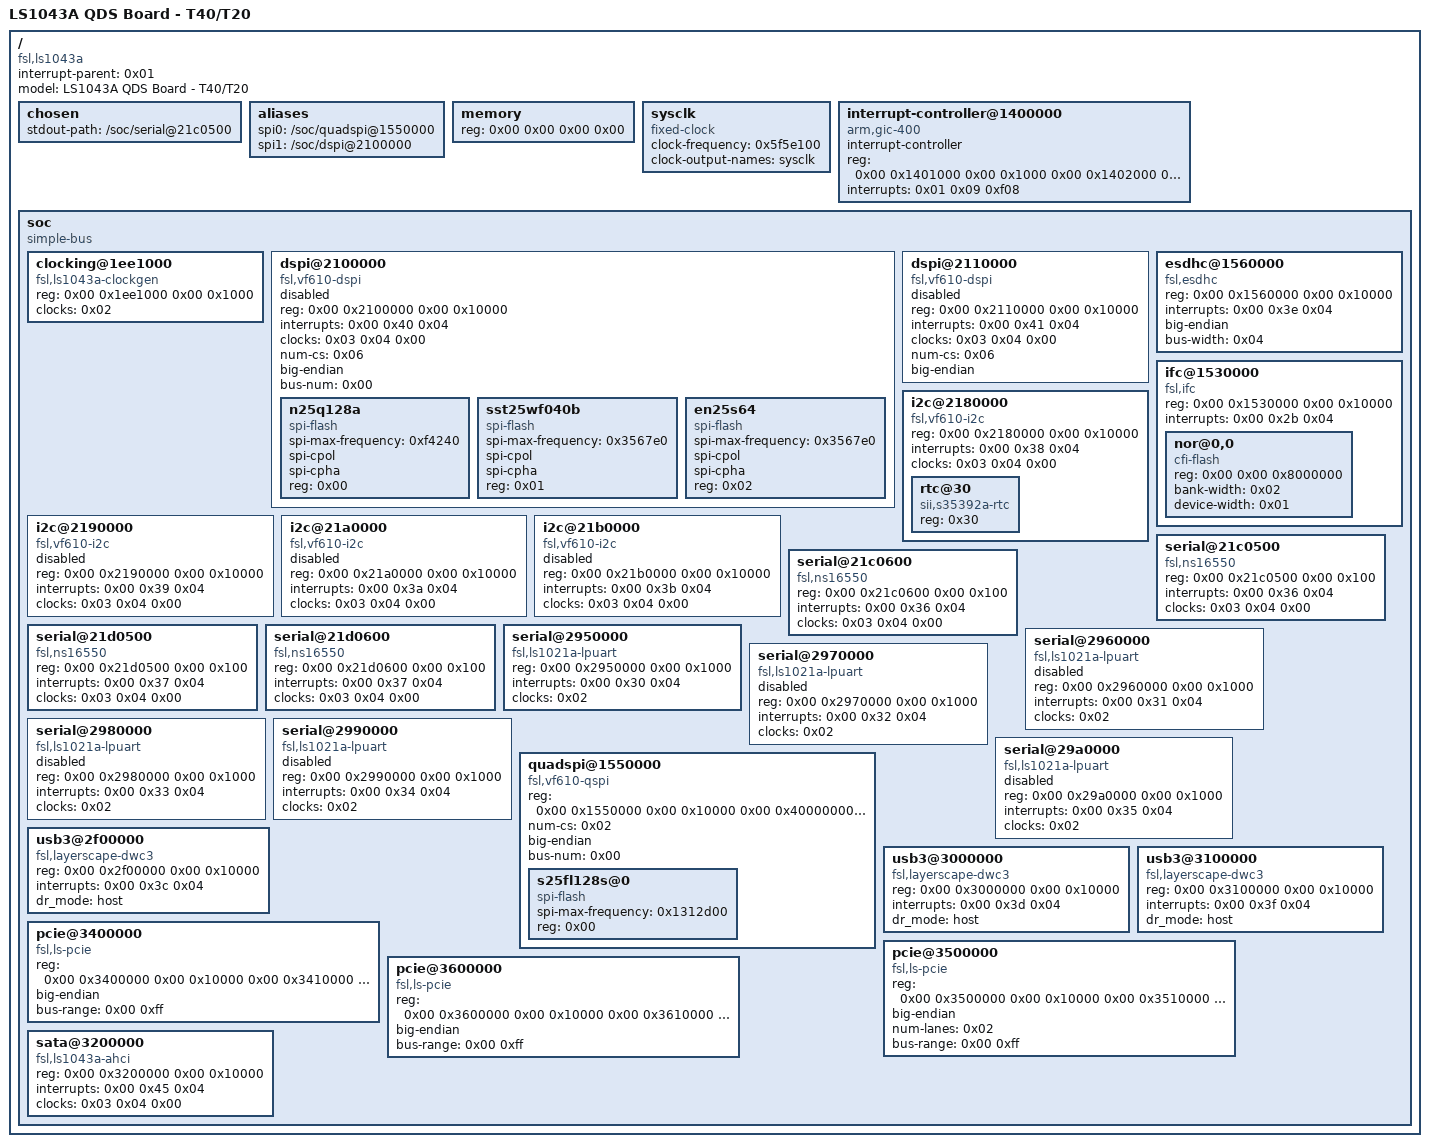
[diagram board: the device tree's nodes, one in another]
/dts-v1/;

/ {
	#address-cells = <0x02>;
	#size-cells = <0x02>;
	compatible = "fsl,ls1043a";
	interrupt-parent = <0x01>;
	model = "LS1043A QDS Board - T40/T20";

	chosen {
		stdout-path = "/soc/serial@21c0500";
	};

	aliases {
		spi0 = "/soc/quadspi@1550000";
		spi1 = "/soc/dspi@2100000";
	};

	memory {
		device_type = "memory";
		reg = <0x00 0x00 0x00 0x00>;
	};

	sysclk {
		compatible = "fixed-clock";
		#clock-cells = <0x00>;
		clock-frequency = <0x5f5e100>;
		clock-output-names = "sysclk";
		phandle = <0x02>;
	};

	interrupt-controller@1400000 {
		compatible = "arm,gic-400";
		#interrupt-cells = <0x03>;
		interrupt-controller;
		reg = <0x00 0x1401000 0x00 0x1000 0x00 0x1402000 0x00 0x2000 0x00 0x1404000 0x00 0x2000 0x00 0x1406000 0x00 0x2000>;
		interrupts = <0x01 0x09 0xf08>;
		phandle = <0x01>;
	};

	soc {
		compatible = "simple-bus";
		#address-cells = <0x02>;
		#size-cells = <0x02>;
		ranges;

		clocking@1ee1000 {
			compatible = "fsl,ls1043a-clockgen";
			reg = <0x00 0x1ee1000 0x00 0x1000>;
			#clock-cells = <0x02>;
			clocks = <0x02>;
			phandle = <0x03>;
		};

		dspi@2100000 {
			compatible = "fsl,vf610-dspi";
			#address-cells = <0x01>;
			#size-cells = <0x00>;
			reg = <0x00 0x2100000 0x00 0x10000>;
			interrupts = <0x00 0x40 0x04>;
			clock-names = "dspi";
			clocks = <0x03 0x04 0x00>;
			num-cs = <0x06>;
			big-endian;
			status = "disabled";
			bus-num = <0x00>;

			n25q128a {
				#address-cells = <0x01>;
				#size-cells = <0x01>;
				compatible = "spi-flash";
				spi-max-frequency = <0xf4240>;
				spi-cpol;
				spi-cpha;
				reg = <0x00>;
			};

			sst25wf040b {
				#address-cells = <0x01>;
				#size-cells = <0x01>;
				compatible = "spi-flash";
				spi-max-frequency = <0x3567e0>;
				spi-cpol;
				spi-cpha;
				reg = <0x01>;
			};

			en25s64 {
				#address-cells = <0x01>;
				#size-cells = <0x01>;
				compatible = "spi-flash";
				spi-max-frequency = <0x3567e0>;
				spi-cpol;
				spi-cpha;
				reg = <0x02>;
			};
		};

		dspi@2110000 {
			compatible = "fsl,vf610-dspi";
			#address-cells = <0x01>;
			#size-cells = <0x00>;
			reg = <0x00 0x2110000 0x00 0x10000>;
			interrupts = <0x00 0x41 0x04>;
			clock-names = "dspi";
			clocks = <0x03 0x04 0x00>;
			num-cs = <0x06>;
			big-endian;
			status = "disabled";
		};

		esdhc@1560000 {
			compatible = "fsl,esdhc";
			reg = <0x00 0x1560000 0x00 0x10000>;
			interrupts = <0x00 0x3e 0x04>;
			big-endian;
			bus-width = <0x04>;
		};

		ifc@1530000 {
			compatible = "fsl,ifc", "simple-bus";
			reg = <0x00 0x1530000 0x00 0x10000>;
			interrupts = <0x00 0x2b 0x04>;
			#address-cells = <0x02>;
			#size-cells = <0x01>;
			ranges = <0x00 0x00 0x00 0x60000000 0x8000000 0x01 0x00 0x00 0x7e800000 0x10000 0x02 0x00 0x00 0x7fb00000 0x100>;
			status = "okay";

			nor@0,0 {
				#address-cells = <0x01>;
				#size-cells = <0x01>;
				compatible = "cfi-flash";
				reg = <0x00 0x00 0x8000000>;
				bank-width = <0x02>;
				device-width = <0x01>;
			};
		};

		i2c@2180000 {
			compatible = "fsl,vf610-i2c";
			#address-cells = <0x01>;
			#size-cells = <0x00>;
			reg = <0x00 0x2180000 0x00 0x10000>;
			interrupts = <0x00 0x38 0x04>;
			clock-names = "i2c";
			clocks = <0x03 0x04 0x00>;
			status = "okay";

			rtc@30 {
				compatible = "sii,s35392a-rtc";
				reg = <0x30>;
			};
		};

		i2c@2190000 {
			compatible = "fsl,vf610-i2c";
			#address-cells = <0x01>;
			#size-cells = <0x00>;
			reg = <0x00 0x2190000 0x00 0x10000>;
			interrupts = <0x00 0x39 0x04>;
			clock-names = "i2c";
			clocks = <0x03 0x04 0x00>;
			status = "disabled";
		};

		i2c@21a0000 {
			compatible = "fsl,vf610-i2c";
			#address-cells = <0x01>;
			#size-cells = <0x00>;
			reg = <0x00 0x21a0000 0x00 0x10000>;
			interrupts = <0x00 0x3a 0x04>;
			clock-names = "i2c";
			clocks = <0x03 0x04 0x00>;
			status = "disabled";
		};

		i2c@21b0000 {
			compatible = "fsl,vf610-i2c";
			#address-cells = <0x01>;
			#size-cells = <0x00>;
			reg = <0x00 0x21b0000 0x00 0x10000>;
			interrupts = <0x00 0x3b 0x04>;
			clock-names = "i2c";
			clocks = <0x03 0x04 0x00>;
			status = "disabled";
		};

		serial@21c0500 {
			compatible = "fsl,ns16550", "ns16550a";
			reg = <0x00 0x21c0500 0x00 0x100>;
			interrupts = <0x00 0x36 0x04>;
			clocks = <0x03 0x04 0x00>;
			status = "okay";
		};

		serial@21c0600 {
			compatible = "fsl,ns16550", "ns16550a";
			reg = <0x00 0x21c0600 0x00 0x100>;
			interrupts = <0x00 0x36 0x04>;
			clocks = <0x03 0x04 0x00>;
			status = "okay";
		};

		serial@21d0500 {
			compatible = "fsl,ns16550", "ns16550a";
			reg = <0x00 0x21d0500 0x00 0x100>;
			interrupts = <0x00 0x37 0x04>;
			clocks = <0x03 0x04 0x00>;
		};

		serial@21d0600 {
			compatible = "fsl,ns16550", "ns16550a";
			reg = <0x00 0x21d0600 0x00 0x100>;
			interrupts = <0x00 0x37 0x04>;
			clocks = <0x03 0x04 0x00>;
		};

		serial@2950000 {
			compatible = "fsl,ls1021a-lpuart";
			reg = <0x00 0x2950000 0x00 0x1000>;
			interrupts = <0x00 0x30 0x04>;
			clocks = <0x02>;
			clock-names = "ipg";
			status = "okay";
		};

		serial@2960000 {
			compatible = "fsl,ls1021a-lpuart";
			reg = <0x00 0x2960000 0x00 0x1000>;
			interrupts = <0x00 0x31 0x04>;
			clocks = <0x02>;
			clock-names = "ipg";
			status = "disabled";
		};

		serial@2970000 {
			compatible = "fsl,ls1021a-lpuart";
			reg = <0x00 0x2970000 0x00 0x1000>;
			interrupts = <0x00 0x32 0x04>;
			clock-names = "ipg";
			clocks = <0x02>;
			status = "disabled";
		};

		serial@2980000 {
			compatible = "fsl,ls1021a-lpuart";
			reg = <0x00 0x2980000 0x00 0x1000>;
			interrupts = <0x00 0x33 0x04>;
			clocks = <0x02>;
			clock-names = "ipg";
			status = "disabled";
		};

		serial@2990000 {
			compatible = "fsl,ls1021a-lpuart";
			reg = <0x00 0x2990000 0x00 0x1000>;
			interrupts = <0x00 0x34 0x04>;
			clocks = <0x02>;
			clock-names = "ipg";
			status = "disabled";
		};

		serial@29a0000 {
			compatible = "fsl,ls1021a-lpuart";
			reg = <0x00 0x29a0000 0x00 0x1000>;
			interrupts = <0x00 0x35 0x04>;
			clocks = <0x02>;
			clock-names = "ipg";
			status = "disabled";
		};

		quadspi@1550000 {
			compatible = "fsl,vf610-qspi";
			#address-cells = <0x01>;
			#size-cells = <0x00>;
			reg = <0x00 0x1550000 0x00 0x10000 0x00 0x40000000 0x00 0x4000000>;
			reg-names = "QuadSPI", "QuadSPI-memory";
			num-cs = <0x02>;
			big-endian;
			status = "okay";
			bus-num = <0x00>;

			s25fl128s@0 {
				#address-cells = <0x01>;
				#size-cells = <0x01>;
				compatible = "spi-flash";
				spi-max-frequency = <0x1312d00>;
				reg = <0x00>;
			};
		};

		usb3@2f00000 {
			compatible = "fsl,layerscape-dwc3";
			reg = <0x00 0x2f00000 0x00 0x10000>;
			interrupts = <0x00 0x3c 0x04>;
			dr_mode = "host";
		};

		usb3@3000000 {
			compatible = "fsl,layerscape-dwc3";
			reg = <0x00 0x3000000 0x00 0x10000>;
			interrupts = <0x00 0x3d 0x04>;
			dr_mode = "host";
		};

		usb3@3100000 {
			compatible = "fsl,layerscape-dwc3";
			reg = <0x00 0x3100000 0x00 0x10000>;
			interrupts = <0x00 0x3f 0x04>;
			dr_mode = "host";
		};

		pcie@3400000 {
			compatible = "fsl,ls-pcie", "snps,dw-pcie";
			reg = <0x00 0x3400000 0x00 0x10000 0x00 0x3410000 0x00 0x10000 0x40 0x00 0x00 0x20000>;
			reg-names = "dbi", "lut", "config";
			big-endian;
			#address-cells = <0x03>;
			#size-cells = <0x02>;
			device_type = "pci";
			bus-range = <0x00 0xff>;
			ranges = <0x81000000 0x00 0x00 0x40 0x20000 0x00 0x10000 0x82000000 0x00 0x40000000 0x40 0x40000000 0x00 0x40000000>;
		};

		pcie@3500000 {
			compatible = "fsl,ls-pcie", "snps,dw-pcie";
			reg = <0x00 0x3500000 0x00 0x10000 0x00 0x3510000 0x00 0x10000 0x48 0x00 0x00 0x20000>;
			reg-names = "dbi", "lut", "config";
			big-endian;
			#address-cells = <0x03>;
			#size-cells = <0x02>;
			device_type = "pci";
			num-lanes = <0x02>;
			bus-range = <0x00 0xff>;
			ranges = <0x81000000 0x00 0x00 0x48 0x20000 0x00 0x10000 0x82000000 0x00 0x40000000 0x48 0x40000000 0x00 0x40000000>;
		};

		pcie@3600000 {
			compatible = "fsl,ls-pcie", "snps,dw-pcie";
			reg = <0x00 0x3600000 0x00 0x10000 0x00 0x3610000 0x00 0x10000 0x50 0x00 0x00 0x20000>;
			reg-names = "dbi", "lut", "config";
			big-endian;
			#address-cells = <0x03>;
			#size-cells = <0x02>;
			device_type = "pci";
			bus-range = <0x00 0xff>;
			ranges = <0x81000000 0x00 0x00 0x50 0x20000 0x00 0x10000 0x82000000 0x00 0x40000000 0x50 0x40000000 0x00 0x40000000>;
		};

		sata@3200000 {
			compatible = "fsl,ls1043a-ahci";
			reg = <0x00 0x3200000 0x00 0x10000>;
			interrupts = <0x00 0x45 0x04>;
			clocks = <0x03 0x04 0x00>;
			status = "okay";
		};
	};
};
